# PIC32CX2051BZ62132 device description
Architecture: CORTEX-M4; Family: PIC32CX; Series: PIC32CXBZ62
Registers are 32-bit, read-write, reset 0x0 unless marked. A register's access mark holds for its fields unless they carry their own. Offsets are from the block's base; [hi:lo] are bit positions; {n}, {i} and the like mark numbered series.

## PMU — PMU SPI controller
Instances: PMU 0x44013E00
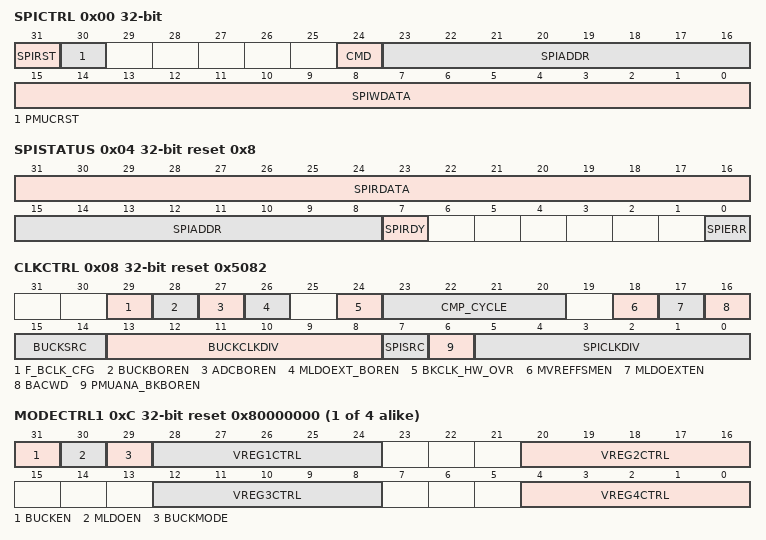
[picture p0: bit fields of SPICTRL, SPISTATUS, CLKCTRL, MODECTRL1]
0x00 SPICTRL
  [31] SPIRST, [30] PMUCRST, [24] CMD, [23:16] SPIADDR, [15:0] SPIWDATA
0x04 SPISTATUS reset 0x8
  [31:16] SPIRDATA, [15:8] SPIADDR, [7] SPIRDY, [0] SPIERR
0x08 CLKCTRL reset 0x5082
  [29] F_BCLK_CFG, [28] BUCKBOREN, [27] ADCBOREN, [26] MLDOEXT_BOREN, [24] BKCLK_HW_OVR, [23:20] CMP_CYCLE, [18] MVREFFSMEN, [17] MLDOEXTEN, [16] BACWD, [15:14] BUCKSRC, [13:8] BUCKCLKDIV, [7] SPISRC, [6] PMUANA_BKBOREN, [5:0] SPICLKDIV
{0x8+4i} MODECTRL{i} reset 0x80000000 (i=1..4)
  [31] BUCKEN, [30] MLDOEN, [29] BUCKMODE, [36-8n:32-8n] VREG{n}CTRL (n=1..4)
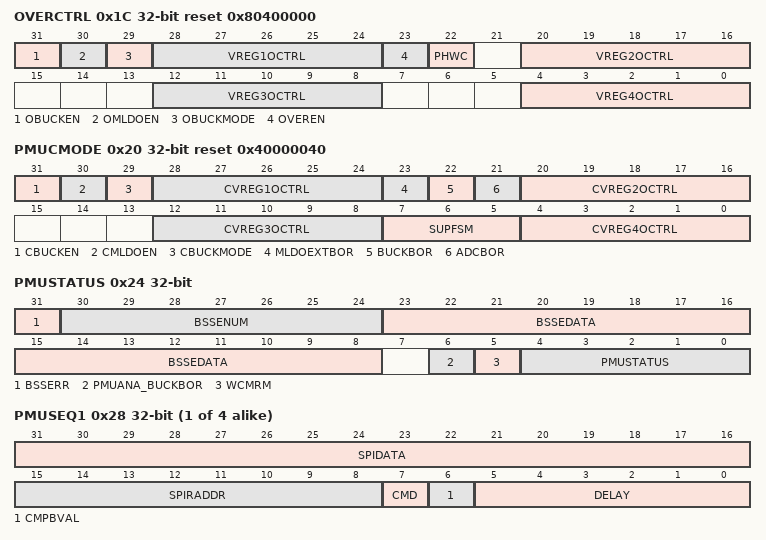
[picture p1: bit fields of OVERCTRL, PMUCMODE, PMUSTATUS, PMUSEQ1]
0x1C OVERCTRL reset 0x80400000
  [31] OBUCKEN, [30] OMLDOEN, [29] OBUCKMODE, [36-8n:32-8n] VREG{n}OCTRL (n=1..4), [23] OVEREN, [22] PHWC
0x20 PMUCMODE reset 0x40000040
  [31] CBUCKEN, [30] CMLDOEN, [29] CBUCKMODE, [36-8n:32-8n] CVREG{n}OCTRL (n=1..4), [23] MLDOEXTBOR, [22] BUCKBOR, [21] ADCBOR, [7:5] SUPFSM
0x24 PMUSTATUS
  [31] BSSERR, [30:24] BSSENUM, [23:8] BSSEDATA, [6] PMUANA_BUCKBOR, [5] WCMRM, [4:0] PMUSTATUS
{0x24+4i} PMUSEQ{i} (i=1..4)
  [31:16] SPIDATA, [15:8] SPIRADDR, [7] CMD, [6] CMPBVAL, [5:0] DELAY
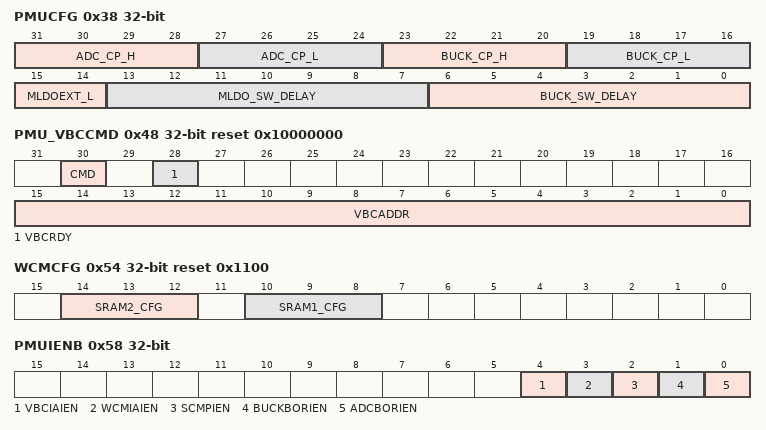
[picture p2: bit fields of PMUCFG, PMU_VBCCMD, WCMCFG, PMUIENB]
0x38 PMUCFG
  [31:28] ADC_CP_H, [27:24] ADC_CP_L, [23:20] BUCK_CP_H, [19:16] BUCK_CP_L, [15:14] MLDOEXT_L, [13:7] MLDO_SW_DELAY, [6:0] BUCK_SW_DELAY
0x48 PMU_VBCCMD reset 0x10000000
  [30] CMD, [28] VBCRDY, [15:0] VBCADDR
0x4C PMU_VBCWDATA
0x50 PMU_VBCRDATA
0x54 WCMCFG reset 0x1100
  [14:12] SRAM2_CFG, [10:8] SRAM1_CFG
0x58 PMUIENB
  [4] VBCIAIEN, [3] WCMIAIEN, [2] SCMPIEN, [1] BUCKBORIEN, [0] ADCBORIEN
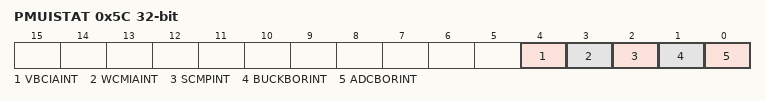
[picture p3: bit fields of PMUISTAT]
0x5C PMUISTAT
  [4] VBCIAINT, [3] WCMIAINT, [2] SCMPINT, [1] BUCKBORINT, [0] ADCBORINT
0x60 WCMSIZ
  [9:8] SRAM1_SIZ
    0=NO_SRAM_RETENTION (FlexRAM is completely powered OFF in deep sleep); 1=16K_SRAM (16K Flex RAM available in retention); 2=32K_SRAM (32K Flex RAM available in retention); 3=64K_SRAM (64K Flex RAM available in retention)

## RAMECC
Instances: RAMECC 0x41008000
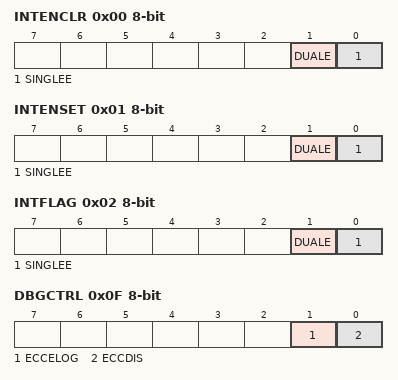
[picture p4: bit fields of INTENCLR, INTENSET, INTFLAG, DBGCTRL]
0x00 INTENCLR 8-bit (atomic clear) — Interrupt Enable Clear
  [1] DUALE — Dual Bit ECC Error Interrupt Enable Clear
  [0] SINGLEE — Single Bit ECC Error Interrupt Enable Clear
0x01 INTENSET 8-bit (atomic set) — Interrupt Enable Set
  [1] DUALE — Dual Bit ECC Error Interrupt Enable Set
  [0] SINGLEE — Single Bit ECC Error Interrupt Enable Set
0x02 INTFLAG 8-bit (atomic clear) — Interrupt Flag
  [1] DUALE — Dual Bit ECC Error Interrupt
  [0] SINGLEE — Single Bit ECC Error Interrupt
0x03 STATUS 8-bit ro
  [0] ECCDIS — ECC Disable
0x04 ERRADDR ro — Error Address
  [17:0] ERRADDR
0x0F DBGCTRL 8-bit — Debug Control
  [1] ECCELOG — ECC Error Log
  [0] ECCDIS — ECC Disable

## WDT — Watch Dog Timer
Instances: WDT 0x44000500
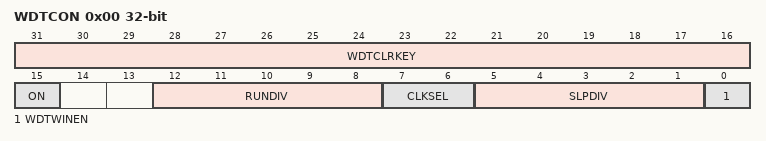
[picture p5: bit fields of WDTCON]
0x00 WDTCON reset not defined — Watchdog Timer Control Register
  [31:16] WDTCLRKEY
  [15] ON — Watchdog Timer Enable bit
    1=WDTEN (The WDT module is enabled); 0=WDTOFF (The WDT module is disabled)
  [12:8] RUNDIV
  [7:6] CLKSEL
  [5:1] SLPDIV
  [0] WDTWINEN — Watchdog Timer Window Enable bit
    1=WDTWINEN (Enable windowed Watchdog Timer); 0=WDTWINDIS (Disable windowed Watchdog Timer)
0x04 WDTCONCLR
0x08 WDTCONSET
0x0C WDTCONINV

## BTZBSYS — BT ZB Subsystem
Instances: BTZBSYS 0x41014000
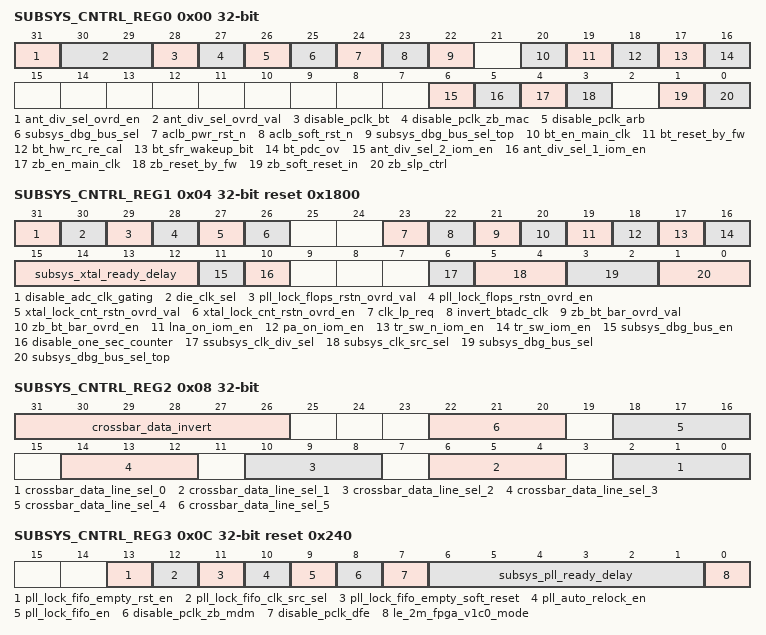
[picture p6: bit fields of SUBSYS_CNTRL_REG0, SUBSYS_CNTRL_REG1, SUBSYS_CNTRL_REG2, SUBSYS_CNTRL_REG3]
0x00 SUBSYS_CNTRL_REG0
  [31] ant_div_sel_ovrd_en, [30:29] ant_div_sel_ovrd_val, [28] disable_pclk_bt, [27] disable_pclk_zb_mac, [26] disable_pclk_arb, [25] subsys_dbg_bus_sel, [24] aclb_pwr_rst_n, [23] aclb_soft_rst_n, [22] subsys_dbg_bus_sel_top, [20] bt_en_main_clk, [19] bt_reset_by_fw, [18] bt_hw_rc_re_cal, [17] bt_sfr_wakeup_bit, [16] bt_pdc_ov, [6] ant_div_sel_2_iom_en, [5] ant_div_sel_1_iom_en, [4] zb_en_main_clk, [3] zb_reset_by_fw, [1] zb_soft_reset_in, [0] zb_slp_ctrl
0x04 SUBSYS_CNTRL_REG1 reset 0x1800
  [31] disable_adc_clk_gating
  [30] die_clk_sel
  [29] pll_lock_flops_rstn_ovrd_val
  [28] pll_lock_flops_rstn_ovrd_en
  [27] xtal_lock_cnt_rstn_ovrd_val
  [26] xtal_lock_cnt_rstn_ovrd_en
  [23] clk_lp_req
  [22] invert_btadc_clk
  [21] zb_bt_bar_ovrd_val
  [20] zb_bt_bar_ovrd_en
  [19] lna_on_iom_en
  [18] pa_on_iom_en
  [17] tr_sw_n_iom_en
  [16] tr_sw_iom_en
  [15:12] subsys_xtal_ready_delay
  [11] subsys_dbg_bus_en
  [10] disable_one_sec_counter
  [6] ssubsys_clk_div_sel — subsys_clk_div_sel
  [5:4] subsys_clk_src_sel
  [3:2] subsys_dbg_bus_sel
  [1:0] subsys_dbg_bus_sel_top
0x08 SUBSYS_CNTRL_REG2
  [31:26] crossbar_data_invert, [4n+2:4n] crossbar_data_line_sel_{n} (n=0..5)
0x0C SUBSYS_CNTRL_REG3 reset 0x240
  [13] pll_lock_fifo_empty_rst_en, [12] pll_lock_fifo_clk_src_sel, [11] pll_lock_fifo_empty_soft_reset, [10] pll_auto_relock_en, [9] pll_lock_fifo_en, [8] disable_pclk_zb_mdm, [7] disable_pclk_dfe, [6:1] subsys_pll_ready_delay, [0] le_2m_fpga_v1c0_mode
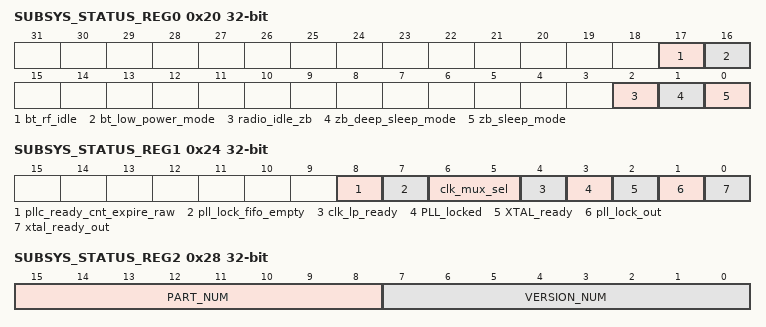
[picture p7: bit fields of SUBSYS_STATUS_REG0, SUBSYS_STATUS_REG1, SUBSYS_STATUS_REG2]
0x20 SUBSYS_STATUS_REG0 ro
  [17] bt_rf_idle, [16] bt_low_power_mode, [2] radio_idle_zb, [1] zb_deep_sleep_mode, [0] zb_sleep_mode
0x24 SUBSYS_STATUS_REG1 ro
  [8] pllc_ready_cnt_expire_raw
  [7] pll_lock_fifo_empty — XTAL_ready
  [6:5] clk_mux_sel — clk_mux_sel0
  [4] clk_lp_ready
  [3] PLL_locked
  [2] XTAL_ready
  [1] pll_lock_out
  [0] xtal_ready_out
0x28 SUBSYS_STATUS_REG2 ro
  [15:8] PART_NUM, [7:0] VERSION_NUM
